AUTOSAR XML (schema 4-3-0)
package /ExamplePackage
  application sw component type Swc1
    provide port p: provided-interface=csi0
  client server interface csi0
  client server interface csi1
  sender receiver interface sri0
  sender receiver interface sri1
  application sw component type Swc2
    provide port P: provided-interface=sri0
package /p1/p2/p3
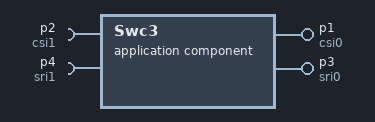
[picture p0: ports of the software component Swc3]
  application sw component type Swc3
    provide port p1: provided-interface=csi0
    require port p2: required-interface=csi1
    provide port p3: provided-interface=sri0
    require port p4: required-interface=sri1
